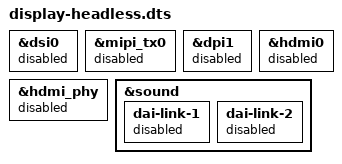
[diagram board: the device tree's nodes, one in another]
/dts-v1/;
/plugin/;

/ {
	fragment@0 {
		target = <&dsi0>;
		__overlay__ {
			status = "disabled";
		};
	};

	fragment@1 {
		target = <&mipi_tx0>;
		__overlay__ {
			status = "disabled";
		};
	};

	fragment@2 {
		target = <&dpi1>;
		__overlay__ {
			status = "disabled";
		};
	};

	fragment@3 {
		target = <&hdmi0>;
		__overlay__ {
			status = "disabled";
		};
	};

	fragment@4 {
		target = <&hdmi_phy>;
		__overlay__ {
			status = "disabled";
		};
	};

	fragment@5 {
		target = <&sound>;
		__overlay__ {
			dai-link-1 { /* HDMI */
				status = "disabled";
			};

			dai-link-2 { /* DPTX */
				status = "disabled";
			};
		};
	};
};
